# LPC800 register map
File version: 0.2
CPU: CM0 r0p0, little endian, no MPU, no FPU, 2 interrupt priority bits
Registers are 32-bit, read-write, reset 0x0 unless marked. A register's access mark holds for its fields unless they carry their own. Offsets are from the block's base; [hi:lo] are bit positions; {n}, {i} and the like mark numbered series.

## MRT — Multi-Rate Timer (MRT)
Base 0x40004000
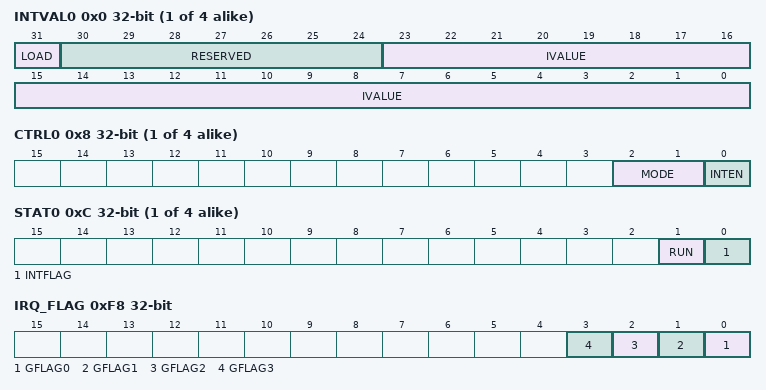
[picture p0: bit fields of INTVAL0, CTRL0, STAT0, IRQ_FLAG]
{0x0+0x10*i} INTVAL{i} (i=0..3) — MRT0 Time interval value register. This value is loaded into the TIMER0 register.
  [31] LOAD — Determines how the timer interval value IVALUE is loaded into the TIMERn register. This bit is write-only. Reading this bit always returns 0.
    0=NO_FORCE_LOAD_THE_L (No force load. The load from the INTVALn register to the TIMERn register is processed at the end of the time interval if the repeat mode is selected.); 1=FORCE_LOAD_THE_INTV (Force load. The INTVALn interval value IVALUE is immediately loaded into the TIMERn register while TIMERn is running.)
  [30:24] RESERVED — Reserved, user software should not write ones to reserved bits. The value read from a reserved bit is not defined.
  [23:0] IVALUE — Time interval load value. This value is loaded into the TIMERn register and the MRTn starts counting down from IVALUE -1. If the timer is idle, writing a non-zero value to this bit field starts the timer immediately. If the timer is running, writing a zero to this bit field does the following: If LOAD = 1, the timer stops immediately. If LOAD = 0, the timer stops at the end of the time interval.
{0x4+0x10*i} TIMER{i} (i=0..3) ro reset 0xFFFFFF — MRT0 Timer register. This register reads the value of the down-counter.
  [23:0] VALUE — Holds the current timer value of the down-counter. The initial value is loaded as IVALUE - 1 from the TIME_INTVALn register either at the end of the time interval if the LOAD bit in TIME_INTVALn is 0 and the timer is in repeat mode or immediately if LOAD = 1. When the timer is in idle state, reading this bit fields returns -1 (0x7FFF FFFF).
{0x8+0x10*i} CTRL{i} (i=0..3) — MRT0 Control register. This register controls the MRT0 modes.
  [2:1] MODE — Selects timer mode.
    0=REPEAT_INTERRUPT_MOD (Repeat interrupt mode.); 1=ONE_SHOT_INTERRUPT_M (One-shot interrupt mode.); 2=ONE_SHOT_BUS_STALL_M (One-shot bus stall mode.)
  [0] INTEN — Enable the TIMERn interrupt.
    0=DISABLE_; 1=ENABLE_
{0xC+0x10*i} STAT{i} (i=0..3) — MRT0 Status register.
  [1] RUN — Indicates the state of TIMERn. This bit is read-only.
    0=IDLE_STATE_TIMERN_I (Idle state. TIMERn is stopped.); 1=RUNNING_TIMERN_IS_R (Running. TIMERn is running.)
  [0] INTFLAG — Monitors the interrupt flag.
    0=NO_PENDING_INTERRUPT (No pending interrupt. Writing a zero is equivalent to no operation.); 1=PENDING_INTERRUPT_T (Pending interrupt. The interrupt is pending because TIMERn has reached the end of the time interval. If the INTEN bit in the CONTROLn is also set to 1, the interrupt for timer channel n and the global interrupt are raised. Writing a 1 to this bit clears the interrupt request.)
0xF4 IDLE_CH ro — Idle channel register. This register returns the number of the first idle channel.
  [7:4] CHAN — Idle channel. Reading the CHAN bits, returns the lowest idle timer channel. If all timer channels are running, CHAN = .
0xF8 IRQ_FLAG — Global interrupt flag register
  [n] GFLAG{n} (n=0..3) — Monitors the interrupt flag of TIMER{n}.
    0=NO_PENDING_INTERRUPT (No pending interrupt. Writing a zero is equivalent to no operation.); 1=PENDING_INTERRUPT_T (Pending interrupt. The interrupt is pending because TIMER{n} has reached the end of the time interval. If the INTEN bit in the CONTROL{n} register is also set to 1, the interrupt for timer channel {n} and the global interrupt are raised. Writing a 1 to this bit clears the interrupt request.)

## WKT — Self wake-up timer (WKT)
Base 0x40008000
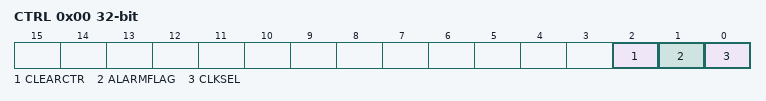
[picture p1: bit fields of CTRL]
0x00 CTRL — Self wake-up timer control register.
  [2] CLEARCTR — Clears the self wake-up timer.
    0=NO_EFFECT_READING_T (No effect. Reading this bit always returns 0.); 1=CLEAR_THE_COUNTER_C (Clear the counter. Counting is halted until a new count value is loaded.)
  [1] ALARMFLAG — Wake-up or alarm timer flag.
    0=NO_TIME_OUT_THE_SEL (No time-out. The self wake-up timer has not timed out. Writing a 0 to has no effect.); 1=TIME_OUT_THE_SELF_W (Time-out. The self wake-up timer has timed out. This flag generates an interrupt request which can wake up the part from any low power mode not deep power-down. Writing a 1 clears this status bit and the interrupt too?)
  [0] CLKSEL — Select the self wake-up timer clock source.
    0=DIVIDED_IRC_CLOCK_T (Divided IRC clock. This clock runs at 750 kHz and provides time-out periods of up to approximately 95 minutes in 1.33 us increments. This clock is not available in most low-power modes and must not be selected if the timer is to be used to wake up from one of these modes.); 1=LOW_POWER_CLOCK_THI (Low power clock. This is the (nominally) 10 kHz clock and provides time-out periods of up to approximately 119 hours in 100 CTS can be from the input pin, or fs increments. The accuracy of this clock is limited to +/- 45 % over temperature and processing. This clock is available in all power modes. Prior to use, the low-power oscillator must be enabled. The oscillator must also be set to remain active in Deep power-down if needed.)
0x0C COUNT reset not defined — Counter register.
  [31:0] VALUE — A write to this register pre-loads start count value into the timer and starts the count-down sequence. A read reflects the current value of the timer.
